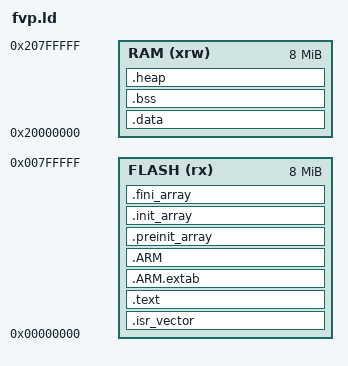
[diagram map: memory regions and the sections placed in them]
/*
 * Copyright (c) 2019-2020, Arm Limited. All rights reserved.
 *
 * SPDX-License-Identifier: BSD-3-Clause
 */

ENTRY(Reset_Handler)

_estack = 0x20000000 + 8M;

MEMORY
{
	FLASH (rx)      : ORIGIN = 0x00000000, LENGTH = 8M
	RAM (xrw)       : ORIGIN = 0x20000000, LENGTH = 8M
}

SECTIONS
{
	/* Reset Vector */
	.isr_vector :
	{
		. = ALIGN(4);
		KEEP(*(.isr_vector))
		. = ALIGN(4);
	} >FLASH

	.text :
	{
		. = ALIGN(4);
		*(.text)
		*(.text*)
		*(.rodata)
		*(.rodata*)
		*(.glue_7)         /* glue arm to thumb code */
		*(.glue_7t)        /* glue thumb to arm code */
		*(.eh_frame)

		KEEP (*(.init))
		KEEP (*(.fini))

		. = ALIGN(4);
		_etext = .;
		_exit = .;
	} >FLASH

	.ARM.extab : { *(.ARM.extab* .gnu.linkonce.armextab.*) } >FLASH
	.ARM : {
		__exidx_start = .;
		*(.ARM.exidx*)
		__exidx_end = .;
	} >FLASH

	.preinit_array :
	{
		PROVIDE_HIDDEN (__preinit_array_start = .);
		KEEP (*(.preinit_array*))
		PROVIDE_HIDDEN (__preinit_array_end = .);
	} >FLASH

	.init_array :
	{
		PROVIDE_HIDDEN (__init_array_start = .);
		KEEP (*(SORT(.init_array.*)))
		KEEP (*(.init_array*))
		PROVIDE_HIDDEN (__init_array_end = .);
	} >FLASH

	.fini_array :
	{
		PROVIDE_HIDDEN (__fini_array_start = .);
		KEEP (*(.fini_array*))
		KEEP (*(SORT(.fini_array.*)))
		PROVIDE_HIDDEN (__fini_array_end = .);
	} >FLASH

	_sidata = .;

	.data : AT ( _sidata )
	{
		. = ALIGN(4);
		_sdata = .;
		*(.data)
		*(.data*)
		. = ALIGN(4);
		_edata = .;
	} >RAM

	. = ALIGN(4);
	.bss :
	{
		__bss_start__ = .;
		*(.bss)
		*(.bss*)
		*(COMMON)
		. = ALIGN(4);
		__bss_end__ = .;
	} >RAM

	.heap : {
		__heap_start__ = .;
		end = __heap_start__;
		_end = end;
		__end = end;
		KEEP(*(.heap))
		__heap_end__ = .;
		HeapLimit = __heap_end__;
	} > RAM

	/* Remove information from the standard libraries */
	/DISCARD/ :
	{
		libc.a ( * )
		libm.a ( * )
		libgcc.a ( * )
	}

	.ARM.attributes 0 : { *(.ARM.attributes) }
}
